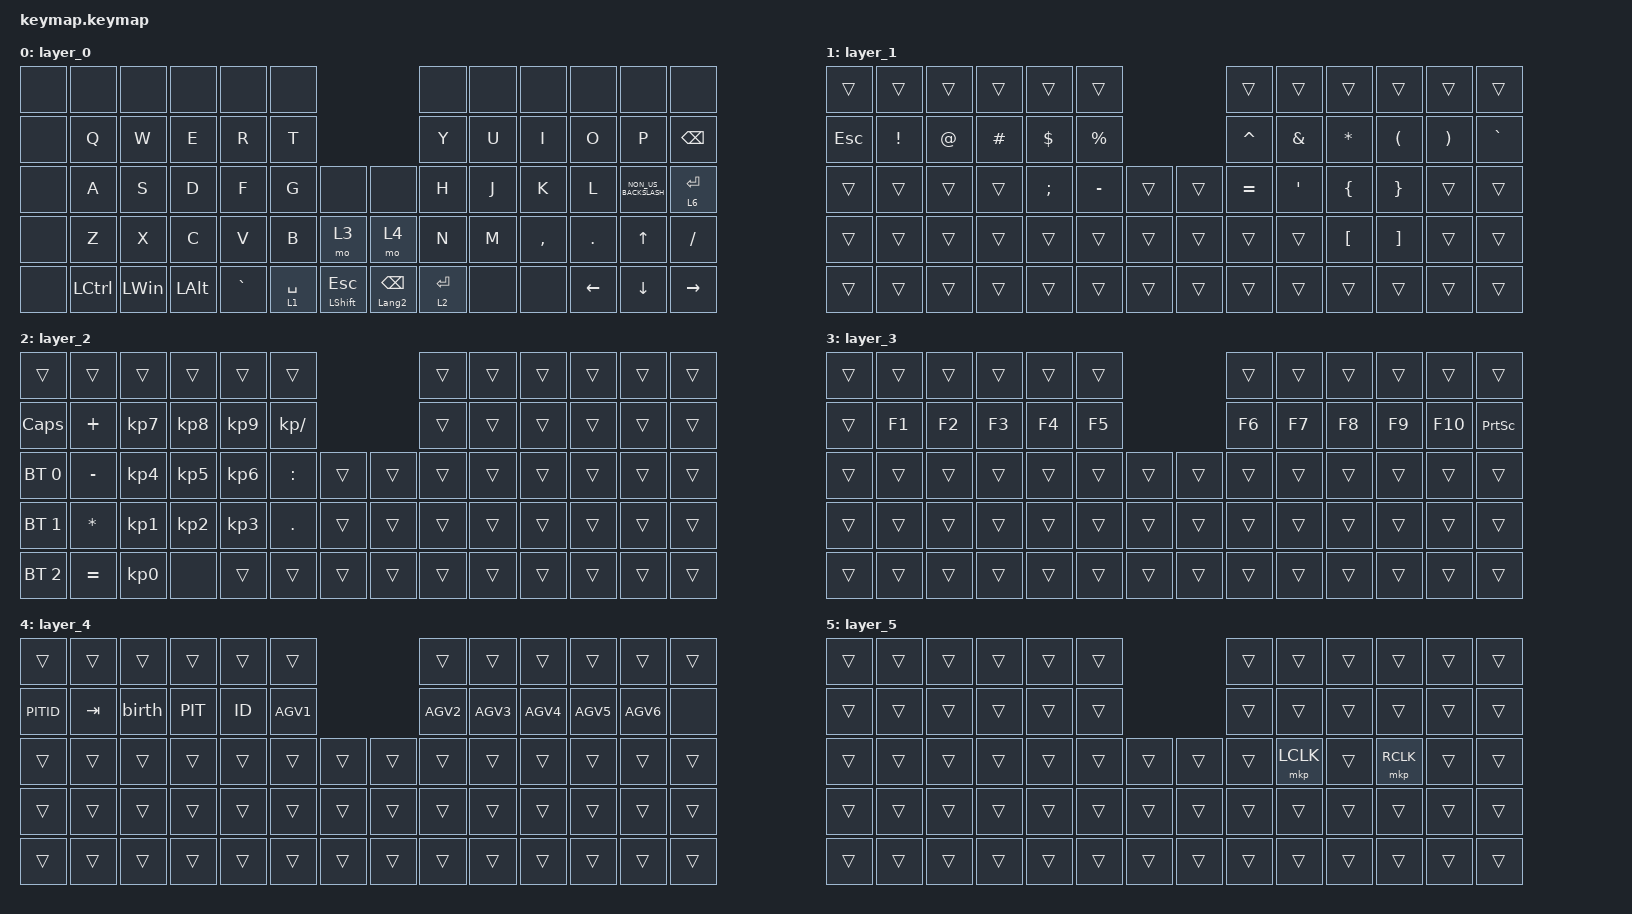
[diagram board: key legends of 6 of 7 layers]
#include <behaviors.dtsi>
#include <dt-bindings/zmk/bt.h>
#include <dt-bindings/zmk/keys.h>
#include <dt-bindings/zmk/pointing.h>

/ {
    combos {
        compatible = "zmk,combos";

        bt_clear {
            bindings = <&bt BT_CLR>;
            key-positions = <28 29>;
            layers = <2>;
        };
    };

    macros {
        PITID: PITID {
            compatible = "zmk,behavior-macro";
            #binding-cells = <0>;
            bindings = <&kp LS(P) &kp LS(I) &kp LS(T) &kp N0 &kp N4 &kp N0 &kp N1 &kp N1 &kp AT &kp B &kp P &kp R &kp DOT &kp B &kp T &kp M &kp DOT &kp C &kp O &kp DOT &kp J &kp P>;
            label = "PITID";
        };

        birth: birth {
            compatible = "zmk,behavior-macro";
            #binding-cells = <0>;
            bindings = <&kp N8 &kp N6 &kp N0 &kp N2 &kp N2 &kp N1>;
            label = "birth";
        };

        PIT: PIT {
            compatible = "zmk,behavior-macro";
            #binding-cells = <0>;
            bindings = <&kp LS(P) &kp LS(I) &kp LS(T) &kp N0 &kp N4 &kp N0 &kp N1 &kp N1>;
            label = "PIT";
        };

        ID: ID {
            compatible = "zmk,behavior-macro";
            #binding-cells = <0>;
            bindings = <&kp N5 &kp N0 &kp N8 &kp N5 &kp N3 &kp N5 &kp N0 &kp N0>;
            label = "ID";
        };

        AGV1: AGV1 {
            compatible = "zmk,behavior-macro";
            #binding-cells = <0>;
            bindings = <&kp POUND &kp LS(A) &kp LS(G) &kp LS(V) &kp N7 &kp N7 &kp N6 &kp N9 &kp N1 &kp A &kp G &kp V &kp POUND>;
            label = "AGV1";
        };

        AGV2: AGV2 {
            compatible = "zmk,behavior-macro";
            #binding-cells = <0>;
            bindings = <&kp POUND &kp LS(A) &kp LS(G) &kp LS(V) &kp N7 &kp N7 &kp N6 &kp N9 &kp N6 &kp A &kp G &kp V &kp POUND>;
            label = "AGV2";
        };

        AGV3: AGV3 {
            compatible = "zmk,behavior-macro";
            #binding-cells = <0>;
            bindings = <&kp POUND &kp LS(A) &kp LS(G) &kp LS(V) &kp N7 &kp N7 &kp N6 &kp N9 &kp N7 &kp A &kp G &kp V &kp POUND>;
            label = "AGV3";
        };

        AGV4: AGV4 {
            compatible = "zmk,behavior-macro";
            #binding-cells = <0>;
            bindings = <&kp POUND &kp LS(A) &kp LS(G) &kp LS(V) &kp N7 &kp N7 &kp N6 &kp N9 &kp N8 &kp A &kp G &kp V &kp POUND>;
            label = "AGV4";
        };

        AGV5: AGV5 {
            compatible = "zmk,behavior-macro";
            #binding-cells = <0>;
            bindings = <&kp POUND &kp LS(A) &kp LS(G) &kp LS(V) &kp N7 &kp N7 &kp N6 &kp N9 &kp N9 &kp A &kp G &kp V &kp POUND>;
            label = "AGV5";
        };

        AGV6: AGV6 {
            compatible = "zmk,behavior-macro";
            #binding-cells = <0>;
            bindings = <&kp POUND &kp LS(A) &kp LS(G) &kp LS(V) &kp N7 &kp N7 &kp N6 &kp N9 &kp N0 &kp A &kp G &kp V &kp POUND>;
            label = "AGV6";
        };

        new_macro: new_macro {
            compatible = "zmk,behavior-macro";
            #binding-cells = <0>;
            bindings = <&none>;
            label = "NEW_MACRO";
        };
    };

    keymap {
        compatible = "zmk,keymap";

        layer_0 {
            bindings = <
&none  &none             &none         &none         &none      &none                                                         &none        &none  &none      &none           &none                 &none
&none  &kp Q             &kp W         &kp E         &kp R      &kp T                                                         &kp Y        &kp U  &kp I      &kp O           &kp P                 &kp BSPC
&none  &kp A             &kp S         &kp D         &kp F      &kp G        &none                  &none                     &kp H        &kp J  &kp K      &kp L           &kp NON_US_BACKSLASH  &lt 6 ENTER
&none  &kp Z             &kp X         &kp C         &kp V      &kp B        &mo 3                  &mo 4                     &kp N        &kp M  &kp COMMA  &kp DOT         &kp UP_ARROW          &kp SLASH
&none  &kp LEFT_CONTROL  &kp LEFT_WIN  &kp LEFT_ALT  &kp GRAVE  &lt 1 SPACE  &mt LEFT_SHIFT ESCAPE  &mt LANGUAGE_2 BACKSPACE  &lt 2 ENTER  &none  &none      &kp LEFT_ARROW  &kp DOWN              &kp RIGHT_ARROW
            >;
        };

        layer_1 {
            bindings = <
&trans   &trans    &trans       &trans    &trans         &trans                       &trans     &trans         &trans            &trans                &trans                 &trans
&kp ESC  &kp EXCL  &kp AT_SIGN  &kp HASH  &kp DOLLAR     &kp PERCENT                  &kp CARET  &kp AMPERSAND  &kp ASTERISK      &kp LEFT_PARENTHESIS  &kp RIGHT_PARENTHESIS  &kp GRAVE
&trans   &trans    &trans       &trans    &kp SEMICOLON  &kp MINUS    &trans  &trans  &kp EQUAL  &kp SQT        &kp LEFT_BRACE    &kp RIGHT_BRACE       &trans                 &trans
&trans   &trans    &trans       &trans    &trans         &trans       &trans  &trans  &trans     &trans         &kp LEFT_BRACKET  &kp RIGHT_BRACKET     &trans                 &trans
&trans   &trans    &trans       &trans    &trans         &trans       &trans  &trans  &trans     &trans         &trans            &trans                &trans                 &trans
            >;
        };

        layer_2 {
            bindings = <
&trans        &trans        &trans           &trans           &trans           &trans                         &trans  &trans  &trans  &trans  &trans  &trans
&kp CAPSLOCK  &kp PLUS      &kp KP_NUMBER_7  &kp KP_NUMBER_8  &kp KP_NUMBER_9  &kp KP_DIVIDE                  &trans  &trans  &trans  &trans  &trans  &trans
&bt BT_SEL 0  &kp MINUS     &kp KP_NUMBER_4  &kp KP_NUMBER_5  &kp KP_NUMBER_6  &kp COLON      &trans  &trans  &trans  &trans  &trans  &trans  &trans  &trans
&bt BT_SEL 1  &kp ASTERISK  &kp KP_NUMBER_1  &kp KP_NUMBER_2  &kp KP_NUMBER_3  &kp PERIOD     &trans  &trans  &trans  &trans  &trans  &trans  &trans  &trans
&bt BT_SEL 2  &kp EQUAL     &kp KP_NUMBER_0  &none            &trans           &trans         &trans  &trans  &trans  &trans  &trans  &trans  &trans  &trans
            >;
        };

        layer_3 {
            bindings = <
&trans  &trans  &trans  &trans  &trans  &trans                  &trans  &trans  &trans  &trans  &trans   &trans
&trans  &kp F1  &kp F2  &kp F3  &kp F4  &kp F5                  &kp F6  &kp F7  &kp F8  &kp F9  &kp F10  &kp PRINTSCREEN
&trans  &trans  &trans  &trans  &trans  &trans  &trans  &trans  &trans  &trans  &trans  &trans  &trans   &trans
&trans  &trans  &trans  &trans  &trans  &trans  &trans  &trans  &trans  &trans  &trans  &trans  &trans   &trans
&trans  &trans  &trans  &trans  &trans  &trans  &trans  &trans  &trans  &trans  &trans  &trans  &trans   &trans
            >;
        };

        layer_4 {
            bindings = <
&trans  &trans   &trans  &trans  &trans  &trans                  &trans  &trans  &trans  &trans  &trans  &trans
&PITID  &kp TAB  &birth  &PIT    &ID     &AGV1                   &AGV2   &AGV3   &AGV4   &AGV5   &AGV6   &none
&trans  &trans   &trans  &trans  &trans  &trans  &trans  &trans  &trans  &trans  &trans  &trans  &trans  &trans
&trans  &trans   &trans  &trans  &trans  &trans  &trans  &trans  &trans  &trans  &trans  &trans  &trans  &trans
&trans  &trans   &trans  &trans  &trans  &trans  &trans  &trans  &trans  &trans  &trans  &trans  &trans  &trans
            >;
        };

        layer_5 {
            bindings = <
&trans  &trans  &trans  &trans  &trans  &trans                  &trans  &trans     &trans  &trans     &trans  &trans
&trans  &trans  &trans  &trans  &trans  &trans                  &trans  &trans     &trans  &trans     &trans  &trans
&trans  &trans  &trans  &trans  &trans  &trans  &trans  &trans  &trans  &mkp LCLK  &trans  &mkp RCLK  &trans  &trans
&trans  &trans  &trans  &trans  &trans  &trans  &trans  &trans  &trans  &trans     &trans  &trans     &trans  &trans
&trans  &trans  &trans  &trans  &trans  &trans  &trans  &trans  &trans  &trans     &trans  &trans     &trans  &trans
            >;
        };

        layer_6 {
            bindings = <
&trans  &trans  &trans  &trans  &trans  &trans                     &trans     &trans  &trans  &trans  &trans  &trans
&trans  &trans  &trans  &trans  &trans  &trans                     &trans     &trans  &trans  &trans  &trans  &trans
&trans  &trans  &trans  &trans  &trans  &trans  &trans  &trans     &trans     &trans  &trans  &trans  &trans  &trans
&trans  &trans  &trans  &trans  &trans  &trans  &trans  &kp LC(C)  &kp LC(V)  &trans  &trans  &trans  &trans  &trans
            >;
        };
    };
};
